# SAMA7G54D4G device description
Architecture: CORTEX-A7; Family: SAMA; Series: SAMA7G
Registers are 32-bit, read-write, reset 0x0 unless marked. A register's access mark holds for its fields unless they carry their own. Offsets are from the block's base; [hi:lo] are bit positions; lines under a group give offsets from that group; {n}, {i} and the like mark numbered series.

## UDDRC (part 1 of 3) — Enhanced Universal DDR-SDRAM Memory Controller
Instances: DDRUMCTL 0xE3800000
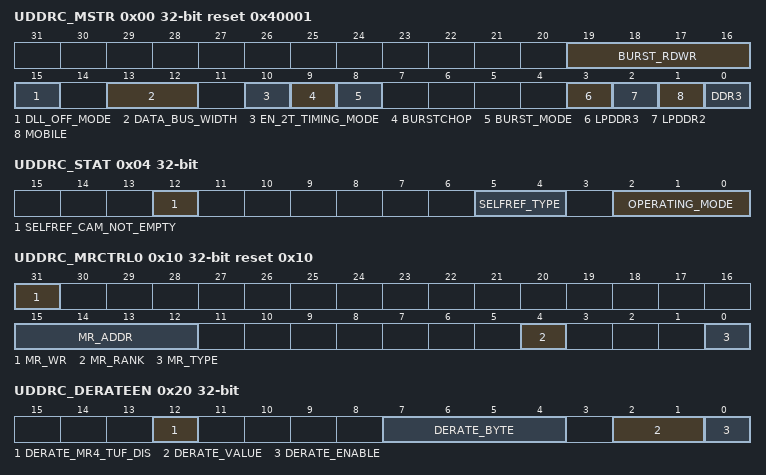
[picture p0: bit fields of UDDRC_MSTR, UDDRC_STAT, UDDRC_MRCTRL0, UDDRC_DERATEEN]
0x00 UDDRC_MSTR reset 0x40001 — Master Register 0
  [19:16] BURST_RDWR — SDRAM burst length used: - 0001 - Burst length of 2 (only supported for mDDR) - 0010 - Burst length of 4 - 0100 - Burst length of 8 - 1000 - Burst length of 16 (only supported for mDDR, LPDDR2, and LPDDR4) All other values are reserved. This controls the burst size used to access the SDRAM. This must match the burst length mode register setting in the SDRAM. (For BC4/8 on-the-fly mode of DDR3 and DDR4, set this field to 0x0100) Burst length of 2 is not supported with AXI ports when MEMC_BURST_LENGTH is 8. Burst length of 2 is only supported when the controller is operating in 1:1 frequency mode. For DDR3, DDR4 and LPDDR3, this must be set to 0x0100 (BL8). For LPDDR4, this must be set to 0x1000 (BL16). Programming Mode: Static
  [15] DLL_OFF_MODE — Set to 1 when the uMCTL2 and DRAM has to be put in DLL-off mode for low frequency operation. Set to 0 to put uMCTL2 and DRAM in DLL-on mode for normal frequency operation. If DDR4 CRC/parity retry is enabled (CRCPARCTL1.crc_parity_retry_enable = 1), dll_off_mode is not supported, and this bit must be set to '0'. Programming Mode: Quasi-dynamic Group 2
  [13:12] DATA_BUS_WIDTH — Selects proportion of DQ bus width that is used by the SDRAM - 00 - Full DQ bus width to SDRAM - 01 - Half DQ bus width to SDRAM - 10 - Quarter DQ bus width to SDRAM - 11 - Reserved. Note that half bus width mode is only supported when the SDRAM bus width is a multiple of 16, and quarter bus width mode is only supported when the SDRAM bus width is a multiple of 32 and the configuration parameter MEMC_QBUS_SUPPORT is set. Bus width refers to DQ bus width (excluding any ECC width). Programming Mode: Static
  [10] EN_2T_TIMING_MODE — If 1, then uMCTL2 uses 2T timing. Otherwise, uses 1T timing. In 2T timing, all command signals (except chip select) are held for 2 clocks on the SDRAM bus. Chip select is asserted on the second cycle of the command Note: - 2T timing is not supported in LPDDR2/LPDDR3/LPDDR4 mode - 2T timing is not supported if the configuration parameter MEMC_CMD_RTN2IDLE is set - 2T timing is not supported in DDR4 geardown mode. - 2T timing is not supported in Shared-AC dual channel mode and the register value is don't care. Programming Mode: Static
  [9] BURSTCHOP — When set, enable burst-chop (BC4 or 8 on-the-fly) in DDR3/DDR4. Burst Chop for Reads is exercised only in HIF configurations (UMCTL2_INCL_ARB not set) and if in full bus width mode (MSTR.data_bus_width = 00) and if MEMC_BURST_LENGTH=8 or 16. Burst Chop for Writes is exercised only if Partial Writes enabled (UMCTL2_PARTIAL_WR=1) and if CRC is disabled (CRCPARCTL1.crc_enable = 0). BC4 (fixed) mode is not supported. Programming Mode: Static
  [8] BURST_MODE — Interleaved burst mode not supported for LpDDR3 - For DDR2 can be set to 1
  [3] LPDDR3 — Select LPDDR3 SDRAM - 1 - LPDDR3 SDRAM device in use. - 0 - non-LPDDR3 device in use Present only in designs configured to support LPDDR3. Programming Mode: Static
  [2] LPDDR2 — Select LPDDR2 SDRAM - 1 - LPDDR2 SDRAM device in use. - 0 - non-LPDDR2 device in use Present only in designs configured to support LPDDR2. Programming Mode: Static
  [1] MOBILE — Select mDDR SDRAM - 1 - Mobile/LPDDR SDRAM device in use - 0 - non-mobile SDRAM device in use This is only present for designs supporting mDDR. Programming Mode: Static
  [0] DDR3 — Select DDR3 SDRAM - 1 - DDR3 SDRAM device in use - 0 - non-DDR3 SDRAM device in use Only present in designs that support DDR3. Programming Mode: Static
0x04 UDDRC_STAT ro — Operating Mode Status Register
  [12] SELFREF_CAM_NOT_EMPTY — Self refresh with CAMs not empty. Set to 1 when Self Refresh is entered but CAMs are not drained. Cleared after exiting Self Refresh. Programming Mode: Static
  [5:4] SELFREF_TYPE — Flags if Self Refresh (except LPDDR4) or SR-Powerdown (LPDDR4) is entered and if it was under Automatic Self Refresh control only or not. - 00 - SDRAM is not in Self Refresh (except LPDDR4) or SR-Powerdown (LPDDR4). If retry is enabled by CRCPARCTRL1.crc_parity_retry_enable, this also indicates SRE command is still in parity error window or retry is in-progress. - 11 - SDRAM is in Self Refresh (except LPDDR4) or SR-Powerdown (LPDDR4), which was caused by Automatic Self Refresh only. If retry is enabled, this guarantees SRE command is executed correctly without parity error. - 10 - SDRAM is in Self Refresh (except LPDDR4) or SR-Powerdown (LPDDR4), which was not caused solely under Automatic Self Refresh control. It could have been caused by Hardware Low Power Interface and/or Software (PWRCTL.selfref_sw). If retry is enabled, this guarantees SRE command is executed correctly without parity error. - 01 - SDRAM is in Self Refresh, which was caused by PHY Master Request. Programming Mode: Static
  [2:0] OPERATING_MODE — Operating mode. This is 3-bits wide in configurations with mDDR/LPDDR2/LPDDR3/LPDDR4/DDR4 support and 2-bits in all other configurations. non-mDDR/LPDDR2/LPDDR3/LPDDR4 and non-DDR4 designs: - 00 - Init - 01 - Normal - 10 - Power-down - 11 - Self refresh mDDR/LPDDR2/LPDDR3 or DDR4 designs: - 000 - Init - 001 - Normal - 010 - Power-down - 011 - Self refresh - 1XX - Deep power-down / Maximum Power Saving Mode LPDDR4 designs: - 000 - Init - 001 - Normal - 010 - Power-down - 011 - Self refresh / Self refresh power-down Programming Mode: Static
0x10 UDDRC_MRCTRL0 reset 0x10 — Mode Register Read/Write Control Register 0
  [31] MR_WR — Setting this register bit to 1 triggers a mode register read or write operation. When the MR operation is complete, the uMCTL2 automatically clears this bit. The other register fields of this register must be written in a separate APB transaction, before setting this mr_wr bit. It is recommended NOT to set this signal if in Init, Deep power-down or MPSM operating modes. Programming Mode: Dynamic
  [15:12] MR_ADDR — Address of the mode register that is to be written to. - 0000 - MR0 - 0001 - MR1 - 0010 - MR2 - 0011 - MR3 - 0100 - MR4 - 0101 - MR5 - 0110 - MR6 - 0111 - MR7 Don't Care for LPDDR2/LPDDR3/LPDDR4 (see MRCTRL1.mr_data for mode register addressing in LPDDR2/LPDDR3/LPDDR4). This signal is also used for writing to control words of the register chip on RDIMMs/LRDIMMs. In that case, it corresponds to the bank address bits sent to the RDIMM/LRDIMM. In case of DDR4, the bit[3:2] corresponds to the bank group bits. Therefore, the bit[3] as well as the bit[2:0] must be set to an appropriate value which is considered both the Address Mirroring of UDIMMs/RDIMMs/LRDIMMs and the Output Inversion of RDIMMs/LRDIMMs. Programming Mode: Dynamic
  [4] MR_RANK — Controls which rank is accessed by MRCTRL0.mr_wr. Normally, it is desired to access all ranks, so all bits should be set to 1. However, for multi-rank UDIMMs/RDIMMs/LRDIMMs which implement address mirroring, it may be necessary to access ranks individually. Examples (assume uMCTL2 is configured for 4 ranks): - 0x1 - select rank 0 only - 0x2 - select rank 1 only - 0x5 - select ranks 0 and 2 - 0xA - select ranks 1 and 3 - 0xF - select ranks 0, 1, 2 and 3 Programming Mode: Dynamic
  [0] MR_TYPE — Indicates whether the mode register operation is read or write. Only used for LPDDR2/LPDDR3/LPDDR4/DDR4. - 0 - Write - 1 - Read Programming Mode: Dynamic
0x14 UDDRC_MRCTRL1 — Mode Register Read/Write Control Register 1
  [15:0] MR_DATA — Mode register write data for all non-LPDDR2/non-LPDDR3/non-LPDDR4 modes. For LPDDR2/LPDDR3/LPDDR4, MRCTRL1[15:0] are interpreted as [15:8] MR Address [7:0] MR data for writes, don't care for reads. This is 18-bits wide in configurations with DDR4 support and 16-bits in all other configurations. Programming Mode: Dynamic
0x18 UDDRC_MRSTAT ro — Mode Register Read/Write Status Register
  [0] MR_WR_BUSY — The SoC core may initiate a MR write operation only if this signal is low. This signal goes high in the clock after the uMCTL2 accepts the MRW/MRR request. It goes low when the MRW/MRR command is issued to the SDRAM. It is recommended not to perform MRW/MRR commands when 'MRSTAT.mr_wr_busy' is high. - 0 - Indicates that the SoC core can initiate a mode register write operation - 1 - Indicates that mode register write operation is in progress Programming Mode: Dynamic
0x20 UDDRC_DERATEEN — Temperature Derate Enable Register
  [12] DERATE_MR4_TUF_DIS — Disable use of MR4 TUF flag (MR4[7]) bit. - 0 - Use MR4 TUF flag (MR4[7]) - 1 - Do not use MR4 TUF Flag (MR4[7]) For LPDDR4, it is recommended to set this register to 1. For LPDDR2 and LPDDR3, please contact your memory vendor for recommended usage. This affects both the periodic derate logic (DERATEEN.derate_enable) and the derate_temp_limit_intr. Programming Mode: Quasi-dynamic Group 2, Group 4
  [7:4] DERATE_BYTE — Derate byte Present only in designs configured to support LPDDR2/LPDDR3/LPDDR4 Indicates which byte of the MRR data is used for derating. The maximum valid value depends on MEMC_DRAM_TOTAL_DATA_WIDTH. Programming Mode: Static
  [2:1] DERATE_VALUE — Derate value - 0 - Derating uses +1 - 1 - Derating uses +2 Present only in designs configured to support LPDDR2/LPDDR3/LPDDR4 Set to 0 for all LPDDR2 speed grades as derating value of +1.875 ns is less than a core_ddrc_core_clk period. For LPDDR3/4, if the period of core_ddrc_core_clk is less than 1.875ns, this register field should be set to 1; otherwise it should be set to 0. Programming Mode: Quasi-dynamic Group 2, Group 4
  [0] DERATE_ENABLE — Enables derating - 0 - Timing parameter derating is disabled - 1 - Timing parameter derating is enabled using MR4 read value. Present only in designs configured to support LPDDR2/LPDDR3/LPDDR4 This field must be set to '0' for non-LPDDR2/LPDDR3/LPDDR4 mode. Programming Mode: Dynamic
0x24 UDDRC_DERATEINT reset 0x800000 — Temperature Derate Interval Register
  [31:0] MR4_READ_INTERVAL — Interval between two MR4 reads, used to derate the timing parameters. Present only in designs configured to support LPDDR2/LPDDR3/LPDDR4. This register must not be set to zero. Unit: DFI clock cycles. Programming Mode: Static
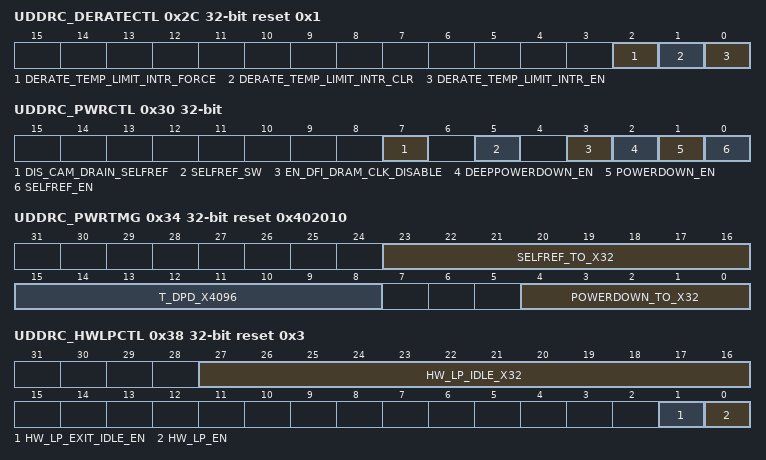
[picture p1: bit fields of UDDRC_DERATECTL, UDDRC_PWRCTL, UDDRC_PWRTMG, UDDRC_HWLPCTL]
0x2C UDDRC_DERATECTL reset 0x1 — Temperature Derate Control Register
  [2] DERATE_TEMP_LIMIT_INTR_FORCE — Interrupt force bit for derate_temp_limit_intr. Setting this register to 1 will cause the derate_temp_limit_intr output pin to be asserted. At the end of the interrupt force operation, the uMCTL2 automatically clears this bit. Programming Mode: Dynamic
  [1] DERATE_TEMP_LIMIT_INTR_CLR — Interrupt clear bit for derate_temp_limit_intr. At the end of the interrupt clear operation, the uMCTL2 automatically clears this bit. Programming Mode: Dynamic
  [0] DERATE_TEMP_LIMIT_INTR_EN — Interrupt enable bit for derate_temp_limit_intr output pin. - 1 Enabled - 0 Disabled Programming Mode: Dynamic
0x30 UDDRC_PWRCTL — Low Power Control Register
  [7] DIS_CAM_DRAIN_SELFREF — Indicates whether skipping CAM draining is allowed when entering Self-Refresh. This register field cannot be modified while PWRCTL.selfref_sw==1. - 0 - CAMs must be empty before entering SR - 1 - CAMs are not emptied before entering SR (unsupported) Note, PWRCTL.dis_cam_drain_selfref=1 is unsupported in this release. PWRCTL.dis_cam_drain_selfref=0 is required. Programming Mode: Dynamic
  [5] SELFREF_SW — A value of 1 to this register causes system to move to Self Refresh state immediately, as long as it is not in INIT or DPD/MPSM operating_mode. This is referred to as Software Entry/Exit to Self Refresh. - 1 - Software Entry to Self Refresh - 0 - Software Exit from Self Refresh Programming Mode: Dynamic
  [3] EN_DFI_DRAM_CLK_DISABLE — Enable the assertion of dfi_dram_clk_disable whenever a clock is not required by the SDRAM. If set to 0, dfi_dram_clk_disable is never asserted. Assertion of dfi_dram_clk_disable is as follows: In DDR2/DDR3, can only be asserted in Self Refresh. In DDR4, can be asserted in following: - in Self Refresh. - in Maximum Power Saving Mode In mDDR/LPDDR2/LPDDR3, can be asserted in following: - in Self Refresh - in Power Down - in Deep Power Down - during Normal operation (Clock Stop) In LPDDR4, can be asserted in following: - in Self Refresh Power Down - in Power Down - during Normal operation (Clock Stop) Programming Mode: Dynamic
  [2] DEEPPOWERDOWN_EN — When this is 1, uMCTL2 puts the SDRAM into deep power-down mode when the transaction store is empty. This register must be reset to '0' to bring uMCTL2 out of deep power-down mode. Controller performs automatic SDRAM initialization on deep power-down exit. Present only in designs configured to support mDDR or LPDDR2 or LPDDR3. For non-mDDR/non-LPDDR2/non-LPDDR3, this register should not be set to 1. FOR PERFORMANCE ONLY. Programming Mode: Dynamic
  [1] POWERDOWN_EN — If true then the uMCTL2 goes into power-down after a programmable number of cycles "maximum idle clocks before power down" (PWRTMG.powerdown_to_x32). This register bit may be re-programmed during the course of normal operation. Programming Mode: Dynamic
  [0] SELFREF_EN — If true then the uMCTL2 puts the SDRAM into Self Refresh after a programmable number of cycles "maximum idle clocks before Self Refresh (PWRTMG.selfref_to_x32)". This register bit may be re-programmed during the course of normal operation. Programming Mode: Dynamic
0x34 UDDRC_PWRTMG reset 0x402010 — Low Power Timing Register
  [23:16] SELFREF_TO_X32 — After this many clocks of the DDRC command channel being idle the uMCTL2 automatically puts the SDRAM into Self Refresh. The DDRC command channel is considered idle when there are no HIF commands outstanding. This must be enabled in the PWRCTL.selfref_en. FOR PERFORMANCE ONLY. Unit: Multiples of 32 DFI clock cycles. Please refer to "Note 1" from "Notes on Timing Registers" at the start of "Register Descriptions" chapter for details on how to program this register field. Programming Mode: Quasi-dynamic Group 4
  [15:8] T_DPD_X4096 — Minimum deep power-down time. For mDDR, value from the JEDEC specification is 0 as mDDR exits from deep power-down mode immediately after PWRCTL.deeppowerdown_en is de-asserted. For LPDDR2/LPDDR3, value from the JEDEC specification is 500us. Present only in designs configured to support mDDR, LPDDR2 or LPDDR3. FOR PERFORMANCE ONLY. Unit: Multiples of 4096 DFI clock cycles. Please refer to "Note 1" from "Notes on Timing Registers" at the start of "Register Descriptions" chapter for details on how to program this register field. Programming Mode: Quasi-dynamic Group 4
  [4:0] POWERDOWN_TO_X32 — After this many clocks of the DDRC command channel being idle the uMCTL2 automatically puts the SDRAM into power-down. The DDRC command channel is considered idle when there are no HIF commands outstanding. This must be enabled in the PWRCTL.powerdown_en. FOR PERFORMANCE ONLY. Unit: Multiples of 32 DFI clock cycles. Please refer to "Note 1" from "Notes on Timing Registers" at the start of "Register Descriptions" chapter for details on how to program this register field. Programming Mode: Quasi-dynamic Group 4
0x38 UDDRC_HWLPCTL reset 0x3 — Hardware Low Power Control Register
  [27:16] HW_LP_IDLE_X32 — Hardware idle period. The cactive_ddrc output is driven low if the DDRC command channel is idle for hw_lp_idle * 32 cycles if not in INIT or DPD/MPSM operating_mode. The DDRC command channel is considered idle when there are no HIF commands outstanding. The hardware idle function is disabled when hw_lp_idle_x32=0. hw_lp_idle_x32=1 is an illegal value. FOR PERFORMANCE ONLY. Unit: Multiples of 32 DFI clock cycles. Please refer to "Note 1" from "Notes on Timing Registers" at the start of "Register Descriptions" chapter for details on how to program this register field. Programming Mode: Static
  [1] HW_LP_EXIT_IDLE_EN — When this bit is programmed to 1 the cactive_in_ddrc pin of the DDRC can be used to exit from the automatic clock stop, automatic power down or automatic self-refresh modes. Note, it will not cause exit of Self-Refresh that was caused by Hardware Low Power Interface and/or Software (PWRCTL.selfref_sw). Programming Mode: Static
  [0] HW_LP_EN — Enable for Hardware Low Power Interface. Programming Mode: Quasi-dynamic Group 2
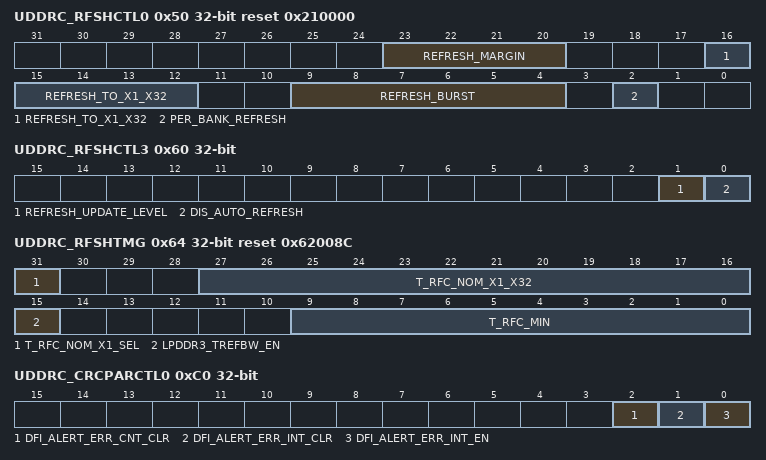
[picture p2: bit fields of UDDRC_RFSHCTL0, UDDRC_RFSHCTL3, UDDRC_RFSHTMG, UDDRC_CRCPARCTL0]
0x50 UDDRC_RFSHCTL0 reset 0x210000 — Refresh Control Register 0
  [23:20] REFRESH_MARGIN — Threshold value in number of DFI clock cycles before the critical refresh or page timer expires. A critical refresh is to be issued before this threshold is reached. It is recommended that this not be changed from the default value, currently shown as 0x2. It must always be less than internally used t_rfc_nom/32. Note that internally used t_rfc_nom is equal to RFSHTMG.t_rfc_nom_x1_x32 * 32 if RFSHTMG.t_rfc_nom_x1_sel=0. If RFSHTMG.t_rfc_nom_x1_sel=1 (for LPDDR2/LPDDR3/LPDDR4 per-bank refresh only), internally used t_rfc_nom is equal to RFSHTMG.t_rfc_nom_x1_x32. Note that, in LPDDR2/LPDDR3/LPDDR4, internally used t_rfc_nom may be divided by four if derating is enabled (DERATEEN.derate_enable=1). Unit: Multiples of 32 DFI clock cycles. Programming Mode: Dynamic - Refresh Related
  [16:12] REFRESH_TO_X1_X32 — If the refresh timer (tRFCnom, also known as tREFI) has expired at least once, then a speculative refresh may be performed. A speculative refresh is a refresh performed at a time when refresh would be useful. When the SDRAM bus is idle for a period of time determined by this RFSHCTL0.refresh_to_x1_x32 and the refresh timer has expired at least once since the last refresh, then a speculative refresh is performed. Speculative refreshes continues successively until there are no refreshes pending or until new reads or writes are issued to the uMCTL2. FOR PERFORMANCE ONLY. Unit: DFI clock cycles or multiples of 32 DFI clock cycles, depending on RFSHTMG.t_rfc_nom_x1_sel. Please refer to "Note 1" from "Notes on Timing Registers" at the start of "Register Descriptions" chapter for details on how to program this register field. Programming Mode: Dynamic - Refresh Related
  [9:4] REFRESH_BURST — The programmed value + 1 is the number of refresh timeouts that is allowed to accumulate before traffic is blocked and the refreshes are forced to execute. Closing pages to perform a refresh is a one-time penalty that must be paid for each group of refreshes. Therefore, performing refreshes in a burst reduces the per-refresh penalty of these page closings. Higher numbers for RFSHCTL.refresh_burst slightly increases utilization; lower numbers decreases the worst-case latency associated with refreshes. - 0 - single refresh - 1 - burst-of-2 refresh - 7 - burst-of-8 refresh For information on burst refresh feature refer to section 3.9 of DDR2 JEDEC specification - JESD79-2F.pdf. For DDR2/3, the refresh is always per-rank and not per-bank. The rank refresh can be accumulated over 8*tREFI cycles using the burst refresh feature. In DDR4 mode, according to Fine Granularity feature, 8 refreshes can be postponed in 1X mode, 16 refreshes in 2X mode and 32 refreshes in 4X mode. If using PHY-initiated updates, care must be taken in the setting of RFSHCTL0.refresh_burst, to ensure that tRFCmax is not violated due to a PHY-initiated update occurring shortly before a refresh burst was due. In this situation, the refresh burst will be delayed until the PHY-initiated update is complete. In per-bank refresh mode of LPDDR2/LPDDR3/LPDDR4 (RFSHCTL0.per_bank_refresh = 1), 64 refreshes can be postponed. Programming Mode: Dynamic - Refresh Related
  [2] PER_BANK_REFRESH — - 1 - Per bank refresh - 0 - All bank refresh Per bank refresh allows traffic to flow to other banks. Per bank refresh is not supported by all LPDDR2 devices but should be supported by all LPDDR3/LPDDR4 devices. Present only in designs configured to support LPDDR2/LPDDR3/LPDDR4 Programming Mode: Static
0x60 UDDRC_RFSHCTL3 — Refresh Control Register 3
  [1] REFRESH_UPDATE_LEVEL — Toggle this signal (either from 0 to 1 or from 1 to 0) to indicate that the refresh register(s) have been updated. refresh_update_level must not be toggled when the DDRC is in reset (core_ddrc_rstn = 0). The refresh register(s) are automatically updated when exiting reset. Programming Mode: Dynamic
  [0] DIS_AUTO_REFRESH — When '1', disable auto-refresh generated by the uMCTL2. When auto-refresh is disabled, the SoC core must generate refreshes using the registers DBGCMD.rankn_refresh. When dis_auto_refresh transitions from 0 to 1, any pending refreshes are immediately scheduled by the uMCTL2. If DDR4 CRC/parity retry is enabled (CRCPARCTL1.crc_parity_retry_enable = 1), disable auto-refresh is not supported, and this bit must be set to '0'. (DDR4 only) If FGR mode is enabled (RFSHCTL3.refresh_mode > 0), disable auto-refresh is not supported, and this bit must be set to '0'. This register field is changeable on the fly. Programming Mode: Dynamic - Refresh Related
0x64 UDDRC_RFSHTMG reset 0x62008C — Refresh Timing Register
  [31] T_RFC_NOM_X1_SEL — Specifies whether the RFSHTMG.t_rfc_nom_x1_x32 and RFSHCTL0.refresh_to_x1_x32 register values are x1 or x32. - 0 - x32 register values are used - 1 - x1 register values are used. This applies only when per-bank refresh is enabled (RFSHCTL0.per_bank_refresh=1); if per-bank refresh is not enabled, the x32 register values are used and this register field is ignored Programming Mode: Dynamic - Refresh Related
  [27:16] T_RFC_NOM_X1_X32 — Average time interval between refreshes per rank (Specification: 7.8us for DDR2, DDR3 and DDR4. See JEDEC specification for mDDR, LPDDR2, LPDDR3 and LPDDR4). When the controller is operating in 1:1 mode, set this register to RoundDown(tREFI/tCK) When the controller is operating in 1:2 mode, set this register to RoundDown(RoundDown(tREFI/tCK)/2) In both the above cases, if RFSHTMG.t_rfc_nom_x1_sel = 0, divide the above result by 32 and round down. For LPDDR2/LPDDR3/LPDDR4: - if using all-bank refreshes (RFSHCTL0.per_bank_refresh = 0), use tREFIab in the above calculations - if using per-bank refreshes (RFSHCTL0.per_bank_refresh = 1), use tREFIpb in the above calculations For DDR4 mode, tREFI value is different depending on the refresh mode. The user should program the appropriate value from the spec based on the value programmed in the refresh mode register. Note that: - RFSHTMG.t_rfc_nom_x1_x32 must be greater than 0x1. - if RFSHTMG.t_rfc_nom_x1_sel == 1, RFSHTMG.t_rfc_nom_x1_x32 must be greater than RFSHTMG.t_rfc_min - if RFSHTMG.t_rfc_nom_x1_sel == 0, RFSHTMG.t_rfc_nom_x1_x32 * 32 must be greater than RFSHTMG.t_rfc_min - In non-DDR4 or DDR4 Fixed 1x mode: RFSHTMG.t_rfc_nom_x1_x32 must be less than or equal to 0xFFE. - In DDR4 Fixed 2x mode: RFSHTMG.t_rfc_nom_x1_x32 must be less than or equal to 0x7FF. - In DDR4 Fixed 4x mode: RFSHTMG.t_rfc_nom_x1_x32 must be less than or equal to 0x3FF. Unit: DFI clock cycles or multiples of 32 DFI clock cycles, depending on RFSHTMG.t_rfc_nom_x1_sel. Please refer to "Note 1" from "Notes on Timing Registers" at the start of "Register Descriptions" chapter for details on how to program this register field. Programming Mode: Dynamic - Refresh Related
  [15] LPDDR3_TREFBW_EN — Used only when LPDDR3 memory type is connected. Should only be changed when uMCTL2 is in reset. Specifies whether to use the tREFBW parameter (required by some LPDDR3 devices which comply with earlier versions of the LPDDR3 JEDEC specification) or not: - 0 - tREFBW parameter not used - 1 - tREFBW parameter used Programming Mode: Static
  [9:0] T_RFC_MIN — tRFC (min): Minimum time from refresh to refresh or activate. When the controller is operating in 1:1 mode, t_rfc_min should be set to RoundUp(tRFCmin/tCK). When the controller is operating in 1:2 mode, t_rfc_min should be set to RoundUp(RoundUp(tRFCmin/tCK)/2). In LPDDR2/LPDDR3/LPDDR4 mode: - if using all-bank refreshes, the tRFCmin value in the above equations is equal to tRFCab - if using per-bank refreshes, the tRFCmin value in the above equations is equal to tRFCpb In DDR4 mode, the tRFCmin value in the above equations is different depending on the refresh mode (fixed 1X,2X,4X) and the device density. The user should program the appropriate value from the spec based on the 'refresh_mode' and the device density that is used. Unit: DFI clock cycles. Programming Mode: Dynamic - Refresh Related
0xC0 UDDRC_CRCPARCTL0 — CRC Parity Control Register0
  [2] DFI_ALERT_ERR_CNT_CLR — DFI alert error count clear. Clear bit for DFI alert error counter. Asserting this bit will clear the DFI alert error counter, CRCPARSTAT.dfi_alert_err_cnt. uMCTL2 automatically clears this bit. Programming Mode: Dynamic
  [1] DFI_ALERT_ERR_INT_CLR — Interrupt clear bit for DFI alert error. If this bit is set, the alert error interrupt on CRCPARSTAT.dfi_alert_err_int will be cleared. uMCTL2 automatically clears this bit. Programming Mode: Dynamic
  [0] DFI_ALERT_ERR_INT_EN — Interrupt enable bit for DFI alert error. If this bit is set, any parity/CRC error detected on the dfi_alert_n input will result in an interrupt being set on CRCPARSTAT.dfi_alert_err_int. Programming Mode: Dynamic
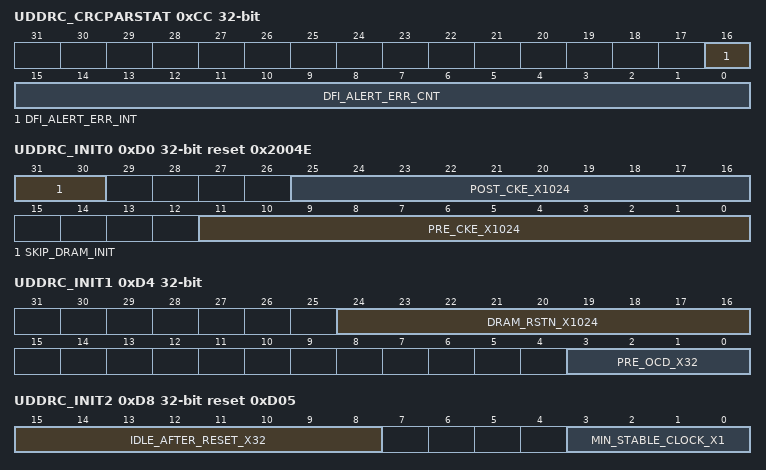
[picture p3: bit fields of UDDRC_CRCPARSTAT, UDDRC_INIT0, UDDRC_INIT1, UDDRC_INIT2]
0xCC UDDRC_CRCPARSTAT ro — CRC Parity Status Register
  [16] DFI_ALERT_ERR_INT — DFI alert error interrupt. If a parity/CRC error is detected on dfi_alert_n, and the interrupt is enabled by CRCPARCTL0.dfi_alert_err_int_en, this interrupt bit will be set. It will remain set until cleared by CRCPARCTL0.dfi_alert_err_int_clr Programming Mode: Static
  [15:0] DFI_ALERT_ERR_CNT — DFI alert error count. If a parity/CRC error is detected on dfi_alert_n, this counter be incremented. This is independent of the setting of CRCPARCTL0.dfi_alert_err_int_en. It will saturate at 0xFFFF, and can be cleared by asserting CRCPARCTL0.dfi_alert_err_cnt_clr. Programming Mode: Static
0xD0 UDDRC_INIT0 reset 0x2004E — SDRAM Initialization Register 0
  [31:30] SKIP_DRAM_INIT — If lower bit is enabled the SDRAM initialization routine is skipped. The upper bit decides what state the controller starts up in when reset is removed - 00 - SDRAM Initialization routine is run after power-up - 01 - SDRAM Initialization routine is skipped after power-up. Controller starts up in Normal Mode - 11 - SDRAM Initialization routine is skipped after power-up. Controller starts up in Self-refresh Mode - 10 - Reserved. Programming Mode: Quasi-dynamic Group 2
  [25:16] POST_CKE_X1024 — Cycles to wait after driving CKE high to start the SDRAM initialization sequence. DDR2 typically requires a 400 ns delay, requiring this value to be programmed to 2 at all clock speeds. LPDDR2/LPDDR3 typically requires this to be programmed for a delay of 200 us. LPDDR4 typically requires this to be programmed for a delay of 2 us. When the controller is operating in 1:2 frequency ratio mode, program this to JEDEC spec value divided by 2, and round it up to the next integer value. Unit: Multiples of 1024 DFI clock cycles. Please refer to "Note 1" from "Notes on Timing Registers" at the start of "Register Descriptions" chapter for details on how to program this register field. Programming Mode: Static
  [11:0] PRE_CKE_X1024 — Cycles to wait after reset before driving CKE high to start the SDRAM initialization sequence. DDR2 specifications typically require this to be programmed for a delay of >= 200 us. LPDDR2/LPDDR3: tINIT1 of 100 ns (min) LPDDR4: tINIT3 of 2 ms (min) When the controller is operating in 1:2 frequency ratio mode, program this to JEDEC spec value divided by 2, and round it up to the next integer value. For DDR3/DDR4 RDIMMs, this should include the time needed to satisfy tSTAB. Unit: Multiples of 1024 DFI clock cycles. Please refer to "Note 1" from "Notes on Timing Registers" at the start of "Register Descriptions" chapter for details on how to program this register field. Programming Mode: Static
0xD4 UDDRC_INIT1 — SDRAM Initialization Register 1
  [24:16] DRAM_RSTN_X1024 — Number of cycles to assert SDRAM reset signal during init sequence. This is only present for designs supporting DDR3, DDR4 or LPDDR4 devices. For use with a Synopsys DDR PHY, this should be set to a minimum of 1. When the controller is operating in 1:2 frequency ratio mode, program this to JEDEC spec value divided by 2, and round it up to the next integer value. Unit: Multiples of 1024 DFI clock cycles. Please refer to "Note 1" from "Notes on Timing Registers" at the start of "Register Descriptions" chapter for details on how to program this register field. Programming Mode: Static
  [3:0] PRE_OCD_X32 — Wait period before driving the OCD complete command to SDRAM. There is no known specific requirement for this; it may be set to zero. Unit: Multiples of 32 DFI clock cycles. Please refer to "Note 1" from "Notes on Timing Registers" at the start of "Register Descriptions" chapter for details on how to program this register field. Programming Mode: Static
0xD8 UDDRC_INIT2 reset 0xD05 — SDRAM Initialization Register 2
  [15:8] IDLE_AFTER_RESET_X32 — Idle time after the reset command, tINIT4. Present only in designs configured to support LPDDR2. When the controller is operating in 1:2 frequency ratio mode, program this to JEDEC spec value divided by 2, and round it up to the next integer value. Unit: Multiples of 32 DFI clock cycles. Please refer to "Note 1" from "Notes on Timing Registers" at the start of "Register Descriptions" chapter for details on how to program this register field. Programming Mode: Static
  [3:0] MIN_STABLE_CLOCK_X1 — Time to wait after the first CKE high, tINIT2. Present only in designs configured to support LPDDR2/LPDDR3. LPDDR2/LPDDR3 typically requires 5 x tCK delay. When the controller is operating in 1:2 frequency ratio mode, program this to JEDEC spec value divided by 2, and round it up to the next integer value. Unit: DFI clock cycles. Programming Mode: Static
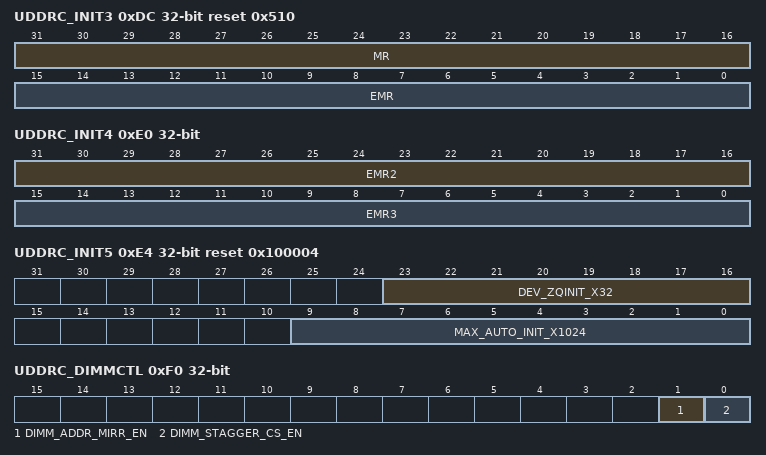
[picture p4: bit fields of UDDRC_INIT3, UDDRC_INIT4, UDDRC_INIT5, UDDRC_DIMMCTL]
0xDC UDDRC_INIT3 reset 0x510 — SDRAM Initialization Register 3
  [31:16] MR — DDR2: Value to write to MR register. Bit 8 is for DLL and the setting here is ignored. The uMCTL2 sets this bit appropriately. DDR3/DDR4: Value loaded into MR0 register. mDDR: Value to write to MR register. LPDDR2/LPDDR3/LPDDR4 - Value to write to MR1 register Programming Mode: Quasi-dynamic Group 1, Group 4
  [15:0] EMR — DDR2: Value to write to EMR register. Bits 9:7 are for OCD and the setting in this register is ignored. The uMCTL2 sets those bits appropriately. DDR3/DDR4: Value to write to MR1 register Set bit 7 to 0. mDDR: Value to write to EMR register. LPDDR2/LPDDR3/LPDDR4 - Value to write to MR2 register Programming Mode: Quasi-dynamic Group 4
0xE0 UDDRC_INIT4 — SDRAM Initialization Register 4
  [31:16] EMR2 — DDR2: Value to write to EMR2 register. DDR3/DDR4: Value to write to MR2 register LPDDR2/LPDDR3/LPDDR4: Value to write to MR3 register mDDR: Unused Programming Mode: Quasi-dynamic Group 4
  [15:0] EMR3 — DDR2: Value to write to EMR3 register. DDR3/DDR4: Value to write to MR3 register mDDR/LPDDR2/LPDDR3: Unused LPDDR4: Value to write to MR13 register Programming Mode: Quasi-dynamic Group 2, Group 4
0xE4 UDDRC_INIT5 reset 0x100004 — SDRAM Initialization Register 5
  [23:16] DEV_ZQINIT_X32 — ZQ initial calibration, tZQINIT. Present only in designs configured to support DDR3 or DDR4 or LPDDR2/LPDDR3. DDR3 typically requires 512 SDRAM clock cycles. DDR4 requires 1024 SDRAM clock cycles. LPDDR2/LPDDR3 requires 1 us. When the controller is operating in 1:2 frequency ratio mode, program this to JEDEC spec value divided by 2, and round it up to the next integer value. Unit: Multiples of 32 DFI clock cycles. Please refer to "Note 1" from "Notes on Timing Registers" at the start of "Register Descriptions" chapter for details on how to program this register field. Programming Mode: Static
  [9:0] MAX_AUTO_INIT_X1024 — Maximum duration of the auto initialization, tINIT5. Present only in designs configured to support LPDDR2/LPDDR3. LPDDR2/LPDDR3 typically requires 10 us. Unit: Multiples of 1024 DFI clock cycles. Please refer to "Note 1" from "Notes on Timing Registers" at the start of "Register Descriptions" chapter for details on how to program this register field. Programming Mode: Static
0xF0 UDDRC_DIMMCTL — DIMM Control Register
  [1] DIMM_ADDR_MIRR_EN — Address Mirroring Enable (for multi-rank UDIMM implementations and multi-rank DDR4 RDIMM/LRDIMM implementations). Some UDIMMs and DDR4 RDIMMs/LRDIMMs implement address mirroring for odd ranks, which means that the following address, bank address and bank group bits are swapped: (A3, A4), (A5, A6), (A7, A8), (BA0, BA1) and also (A11, A13), (BG0, BG1) for the DDR4. Setting this bit ensures that, for mode register accesses during the automatic initialization routine, these bits are swapped within the uMCTL2 to compensate for this UDIMM/RDIMM/LRDIMM swapping. In addition to the automatic initialization routine, in case of DDR4 UDIMM/RDIMM/LRDIMM, they are swapped during the automatic MRS access to enable/disable of a particular DDR4 feature. Note: This has no effect on the address of any other memory accesses, or of software-driven mode register accesses. This is not supported for mDDR, LPDDR2, LPDDR3 or LPDDR4 SDRAMs. Note: In case of x16 DDR4 DIMMs, BG1 output of MRS for the odd ranks is same as BG0 because BG1 is invalid, hence dimm_dis_bg_mirroring register must be set to 1. - 1 - For odd ranks, implement address mirroring for MRS commands to during initialization and for any automatic DDR4 MRS commands (to be used if UDIMM/RDIMM/LRDIMM implements address mirroring) - 0 - Do not implement address mirroring Programming Mode: Static
  [0] DIMM_STAGGER_CS_EN — Staggering enable for multi-rank accesses (for multi-rank UDIMM, RDIMM and LRDIMM implementations only). This is not supported for mDDR, LPDDR2, LPDDR3 or LPDDR4 SDRAMs. Note: Even if this bit is set it does not take care of software driven MR commands (via MRCTRL0/MRCTRL1), where software is responsible to send them to seperate ranks as appropriate. - 1 - (DDR4) Send MRS commands to each ranks seperately - 1 - (non-DDR4) Send all commands to even and odd ranks seperately - 0 - Do not stagger accesses Programming Mode: Static
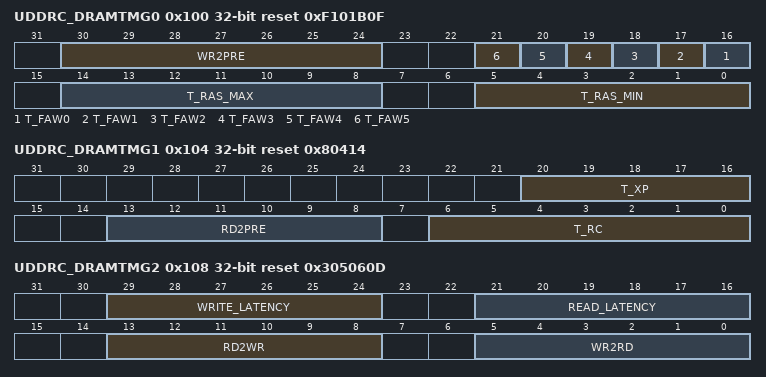
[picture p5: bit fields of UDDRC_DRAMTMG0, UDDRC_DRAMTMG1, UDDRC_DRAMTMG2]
0x100 UDDRC_DRAMTMG0 reset 0xF101B0F — SDRAM Timing Register 0
  [30:24] WR2PRE — Minimum time between write and precharge to same bank. Specifications: WL + BL/2 + tWR = approximately 8 cycles + 15 ns = 14 clocks @400MHz and less for lower frequencies where: - WL = write latency - BL = burst length. This must match the value programmed in the BL bit of the mode register to the SDRAM. BST (burst terminate) is not supported at present. - tWR = Write recovery time. This comes directly from the SDRAM specification. Add one extra cycle for LPDDR2/LPDDR3/LPDDR4 for this parameter. When the controller is operating in 1:2 frequency ratio mode, 1T mode, divide the above value by 2. No rounding up. When the controller is operating in 1:2 frequency ratio mode, 2T mode or LPDDR4 mode, divide the above value by 2 and round it up to the next integer value. Note that, depending on the PHY, if using LRDIMM, it may be necessary to adjust the value of this parameter to compensate for the extra cycle of latency through the LRDIMM. Unit: DFI clock cycles. Programming Mode: Quasi-dynamic Group 1, Group 2, Group 4
  [n+16] T_FAW{n} (n=0..5) — tFAW Valid only when 8 or more banks(or banks {n} bank groups) are present. In 8-bank design, at most 4 banks must be activated in a rolling window of tFAW cycles. When the controller is operating in 1:2 frequency ratio mode, program this to (tFAW/2) and round up to next integer value. In a 4-bank design, set this register to 0x1 independent of the 1:1/1:2 frequency mode. Unit: DFI clock cycles. Programming Mode: Quasi-dynamic Group 2, Group 4
  [14:8] T_RAS_MAX — tRAS(max): Maximum time between activate and precharge to same bank. This is the maximum time that a page can be kept open Minimum value of this register is 1. Zero is invalid. When the controller is operating in 1:1 frequency ratio mode, t_ras_max should be set to RoundDown(tRAS(max)/tCK/1024). When the controller is operating in 1:2 frequency ratio mode, t_ras_max should be set to RoundDown((RoundDown(tRAS(max)/tCK/1024)-1)/2). Unit: Multiples of 1024 DFI clock cycles. Programming Mode: Quasi-dynamic Group 2, Group 4
  [5:0] T_RAS_MIN — tRAS(min): Minimum time between activate and precharge to the same bank. When the controller is operating in 1:2 frequency mode, 1T mode, program this to tRAS(min)/2. No rounding up. When the controller is operating in 1:2 frequency ratio mode, 2T mode or LPDDR4 mode, program this to (tRAS(min)/2) and round it up to the next integer value. Unit: DFI clock cycles. Programming Mode: Quasi-dynamic Group 2, Group 4
0x104 UDDRC_DRAMTMG1 reset 0x80414 — SDRAM Timing Register 1
  [20:16] T_XP — tXP: Minimum time after power-down exit to any operation. For DDR3, this should be programmed to tXPDLL if slow powerdown exit is selected in MR0[12]. If C/A parity for DDR4 is used, set to (tXP+PL) instead. If LPDDR4 is selected and its spec has tCKELPD parameter, set to the larger of tXP and tCKELPD instead. When the controller is operating in 1:2 frequency ratio mode, program this to (tXP/2) and round it up to the next integer value. Units: DFI clock cycles. Programming Mode: Quasi-dynamic Group 2, Group 4
  [13:8] RD2PRE — tRTP: Minimum time from read to precharge of same bank. - DDR2: tAL + BL/2 + max(tRTP, 2) - 2 - DDR3: tAL + max (tRTP, 4) - DDR4: Max of following two equations: tAL + max (tRTP, 4) or, RL + BL/2 - tRP (*). - mDDR: BL/2 - LPDDR2: Depends on if it's LPDDR2-S2 or LPDDR2-S4: LPDDR2-S2: BL/2 + tRTP - 1. LPDDR2-S4: BL/2 + max(tRTP,2) - 2. - LPDDR3: BL/2 + max(tRTP,4) - 4 - LPDDR4: BL/2 + max(tRTP,8) - 8 (*) When both DDR4 SDRAM and ST-MRAM are used simultaneously, use SDRAM's tRP value for calculation. When the controller is operating in 1:2 mode, 1T mode, divide the above value by 2. No rounding up. When the controller is operating in 1:2 mode, 2T mode or LPDDR4 mode, divide the above value by 2 and round it up to the next integer value. Unit: DFI clock cycles. Programming Mode: Quasi-dynamic Group 1, Group 2, Group 4
  [6:0] T_RC — tRC: Minimum time between activates to same bank. When the controller is operating in 1:2 frequency ratio mode, program this to (tRC/2) and round up to next integer value. Unit: DFI clock cycles. Programming Mode: Quasi-dynamic Group 2, Group 4
0x108 UDDRC_DRAMTMG2 reset 0x305060D — SDRAM Timing Register 2
  [29:24] WRITE_LATENCY — Set to WL Time from write command to write data on SDRAM interface. This must be set to WL. For mDDR, it should normally be set to 1. Note that, depending on the PHY, if using RDIMM/LRDIMM, it may be necessary to adjust the value of WL to compensate for the extra cycle of latency through the RDIMM/LRDIMM. When the controller is operating in 1:2 frequency ratio mode, divide the value calculated using the above equation by 2, and round it up to next integer. This register field is not required for DDR2 and DDR3, as the DFI read and write latencies defined in DFITMG0 and DFITMG1 are sufficient for those protocols For all protocols, in addition to programming this register field, it is necessary to program DFITMG0 and DFITMG1 to control the read and write latencies Unit: DFI clock cycles. Programming Mode: Quasi-dynamic Group 1, Group 2, Group 4
  [21:16] READ_LATENCY — Set to RL Time from read command to read data on SDRAM interface. This must be set to RL. Note that, depending on the PHY, if using RDIMM/LRDIMM, it may be necessary to adjust the value of RL to compensate for the extra cycle of latency through the RDIMM/LRDIMM. When the controller is operating in 1:2 frequency ratio mode, divide the value calculated using the above equation by 2, and round it up to next integer. This register field is not required for DDR2 and DDR3, as the DFI read and write latencies defined in DFITMG0 and DFITMG1 are sufficient for those protocols For all protocols, in addition to programming this register field, it is necessary to program DFITMG0 and DFITMG1 to control the read and write latencies Unit: DFI clock cycles. Programming Mode: Quasi-dynamic Group 1, Group 2, Group 4
  [13:8] RD2WR — DDR2/3/mDDR: RL + BL/2 + 2 - WL DDR4: RL + BL/2 + 1 + WR_PREAMBLE - WL LPDDR2/LPDDR3: RL + BL/2 + RU(tDQSCKmax/tCK) + 1 - WL LPDDR4(DQ ODT is Disabled): RL + BL/2 + RU(tDQSCKmax/tCK) + WR_PREAMBLE + RD_POSTAMBLE - WL LPDDR4(DQ ODT is Enabled) : RL + BL/2 + RU(tDQSCKmax/tCK) + RD_POSTAMBLE - ODTLon - RU(tODTon(min)/tCK) + 1 Minimum time from read command to write command. Include time for bus turnaround and all per-bank, per-rank, and global constraints. Please see the relevant PHY databook for details of what should be included here. Where: - WL = write latency - BL = burst length. This must match the value programmed in the BL bit of the mode register to the SDRAM - RL = read latency = CAS latency - WR_PREAMBLE = 1 (1tCK write preamble), 2 (2tCK write preamble). This is unique to DDR4 and LPDDR4. - RD_POSTAMBLE = 0.5 (0.5tCK read postamble), 1.5 (1.5tCK read postamble). This is unique to LPDDR4. After PHY has completed training the value programmed may need to be increased. Refer to relevant PHY documentation. For LPDDR2/LPDDR3/LPDDR4, if derating is enabled (DERATEEN.derate_enable=1), derated tDQSCKmax should be used. When the controller is operating in 1:2 frequency ratio mode, divide the value calculated using the above equation by 2, and round it up to next integer. Note that, depending on the PHY, if using LRDIMM, it may be necessary to adjust the value of this parameter to compensate for the extra cycle of latency through the LRDIMM. Unit: DFI clock cycles. Programming Mode: Quasi-dynamic Group 1, Group 2, Group 4
  [5:0] WR2RD — DDR4: CWL + PL + BL/2 + tWTR_L LPDDR2/3/4: WL + BL/2 + tWTR + 1 Others: CWL + BL/2 + tWTR In DDR4, minimum time from write command to read command for same bank group. In others, minimum time from write command to read command. Includes time for bus turnaround, recovery times, and all per-bank, per-rank, and global constraints. Please see the relevant PHY databook for details of what should be included here. Where: - CWL = CAS write latency - WL = Write latency - PL = Parity latency - BL = burst length. This must match the value programmed in the BL bit of the mode register to the SDRAM - tWTR_L = internal write to read command delay for same bank group. This comes directly from the SDRAM specification. - tWTR = internal write to read command delay. This comes directly from the SDRAM specification. After PHY has completed training the value programmed may need to be increased. Refer to relevant PHY documentation. Add one extra cycle for LPDDR2/LPDDR3/LPDDR4 operation. WTR_L should be increased by one if DDR4 2tCK write preamble is used. When the controller is operating in 1:2 mode, divide the value calculated using the above equation by 2, and round it up to next integer. Unit: DFI clock cycles. Programming Mode: Quasi-dynamic Group 1, Group 2, Group 4
